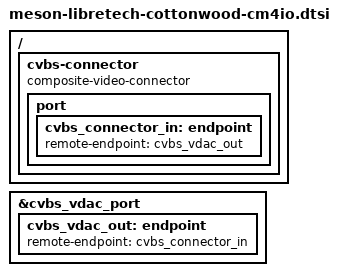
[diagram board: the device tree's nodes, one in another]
// SPDX-License-Identifier: (GPL-2.0+ OR MIT)
/*
 * Libre Computer Cottonwood CM on RPi CM4IO carrier board
 *
 * CM4IO-specific hardware not present on CM5IO:
 * - CVBS composite video connector (pin 111 = VDAC_COMP)
 *   CM5IO repurposes pin 111 for VBUS_EN, so no CVBS.
 *
 * Other CM4IO features not yet in DT:
 * - PCF85063AT RTC at I2C 0x51 (pins 80/82, AML i2c1 GPIOH_6/H_7)
 * - EMC2301 fan controller at I2C 0x2f (same bus)
 * - 12V barrel jack power input (carrier steps down to 5V)
 */

/ {
	/* TOFIX: handle CVBS_DET on SARADC channel 0 */
	cvbs-connector {
		compatible = "composite-video-connector";

		port {
			cvbs_connector_in: endpoint {
				remote-endpoint = <&cvbs_vdac_out>;
			};
		};
	};
};

&cvbs_vdac_port {
	cvbs_vdac_out: endpoint {
		remote-endpoint = <&cvbs_connector_in>;
	};
};
